VERSION ""

NS_ :

BS_:

BU_:

BO_ 1285 Driver_Controls: 8 Vector__XXX
	SG_ State : 0|16@1+ (1,0) [0|0] "" Vector__XXX

BO_ 1536 BMU_Heatbeat: 0 Vector__XXX
	SG_  : 0|0@1+ (0,0) [0|0] "" Vector__XXX

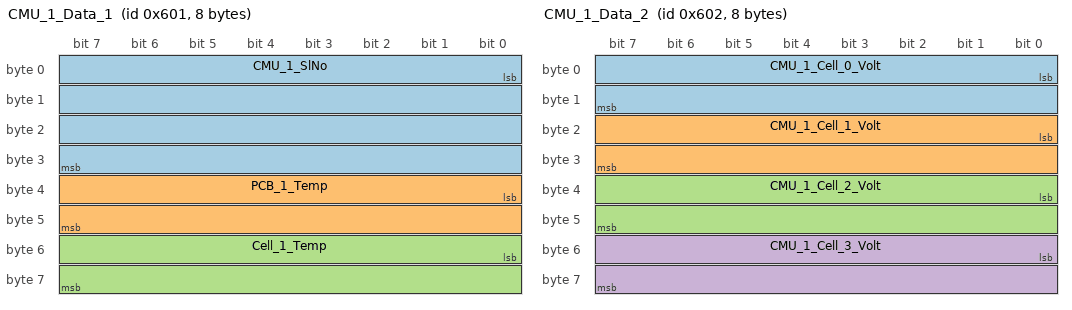
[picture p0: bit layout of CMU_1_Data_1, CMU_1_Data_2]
BO_ 1537 CMU_1_Data_1: 8 Vector__XXX
	SG_ CMU_1_SlNo : 0|32@1+ (1,0) [0|0] "" Vector__XXX
	SG_ PCB_1_Temp : 32|16@1+ (0.1,0) [0|0] "Celcius" Vector__XXX
	SG_ Cell_1_Temp : 48|16@1+ (0.1,0) [0|0] "Celcius" Vector__XXX

BO_ 1538 CMU_1_Data_2: 8 Vector__XXX
	SG_ CMU_1_Cell_0_Volt : 0|16@1+ (1,0) [0|0] "mV" Vector__XXX
	SG_ CMU_1_Cell_1_Volt : 16|16@1+ (1,0) [0|0] "mV" Vector__XXX
	SG_ CMU_1_Cell_2_Volt : 32|16@1+ (1,0) [0|0] "mV" Vector__XXX
	SG_ CMU_1_Cell_3_Volt : 48|16@1+ (1,0) [0|0] "mV" Vector__XXX

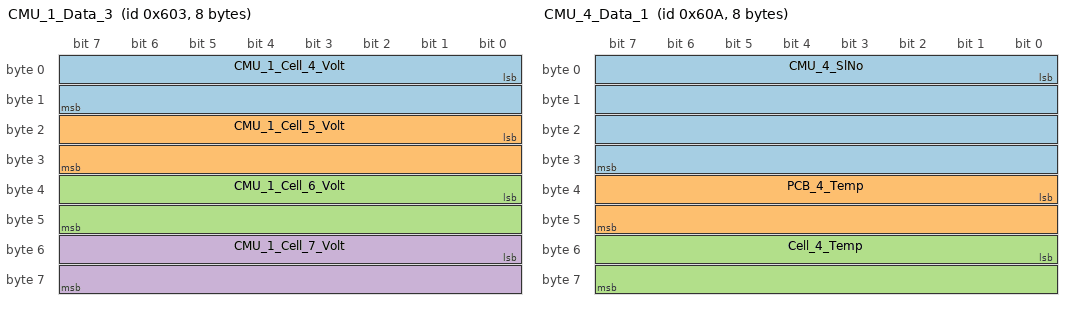
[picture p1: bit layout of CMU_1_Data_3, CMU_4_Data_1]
BO_ 1539 CMU_1_Data_3: 8 Vector__XXX
	SG_ CMU_1_Cell_4_Volt : 0|16@1+ (1,0) [0|0] "mV" Vector__XXX
	SG_ CMU_1_Cell_5_Volt : 16|16@1+ (1,0) [0|0] "mV" Vector__XXX
	SG_ CMU_1_Cell_6_Volt : 32|16@1+ (1,0) [0|0] "mV" Vector__XXX
	SG_ CMU_1_Cell_7_Volt : 48|16@1+ (1,0) [0|0] "mV" Vector__XXX

BO_ 1540 CMU_2_Data_1: 0 Vector__XXX
	SG_ CMU_2_SlNo : 0|32@1+ (1,0) [0|0] "" Vector__XXX
	SG_ PCB_2_Temp : 32|16@1+ (0.1,0) [0|0] "Celcius" Vector__XXX
	SG_ Cell_2_Temp : 48|16@1+ (0.1,0) [0|0] "Celcius" Vector__XXX

BO_ 1541 CMU_2_Data_2: 0 Vector__XXX
	SG_ CMU_2_Cell_0_Volt : 0|16@1+ (1,0) [0|0] "mV" Vector__XXX
	SG_ CMU_2_Cell_1_Volt : 16|16@1+ (1,0) [0|0] "mV" Vector__XXX
	SG_ CMU_2_Cell_2_Volt : 32|16@1+ (1,0) [0|0] "mV" Vector__XXX
	SG_ CMU_2_Cell_3_Volt : 48|16@1+ (1,0) [0|0] "mV" Vector__XXX

BO_ 1542 CMU_2_Data_3: 0 Vector__XXX
	SG_ CMU_2_Cell_4_Volt : 0|16@1+ (1,0) [0|0] "mV" Vector__XXX
	SG_ CMU_2_Cell_5_Volt : 16|16@1+ (1,0) [0|0] "mV" Vector__XXX
	SG_ CMU_2_Cell_6_Volt : 32|16@1+ (1,0) [0|0] "mV" Vector__XXX
	SG_ CMU_2_Cell_7_Volt : 48|16@1+ (1,0) [0|0] "mV" Vector__XXX

BO_ 1543 CMU_3_Data_1: 0 Vector__XXX
	SG_ CMU_3_SlNo : 0|32@1+ (1,0) [0|0] "" Vector__XXX
	SG_ PCB_3_Temp : 32|16@1+ (0.1,0) [0|0] "Celcius" Vector__XXX
	SG_ Cell_3_Temp : 48|16@1+ (0.1,0) [0|0] "Celcius" Vector__XXX

BO_ 1544 CMU_3_Data_2: 0 Vector__XXX
	SG_ CMU_3_Cell_0_Volt : 0|16@1+ (1,0) [0|0] "mV" Vector__XXX
	SG_ CMU_3_Cell_1_Volt : 16|16@1+ (1,0) [0|0] "mV" Vector__XXX
	SG_ CMU_3_Cell_2_Volt : 32|16@1+ (1,0) [0|0] "mV" Vector__XXX
	SG_ CMU_3_Cell_3_Volt : 48|16@1+ (1,0) [0|0] "mV" Vector__XXX

BO_ 1545 CMU_3_Data_3: 0 Vector__XXX
	SG_ CMU_3_Cell_4_Volt : 0|16@1+ (1,0) [0|0] "mV" Vector__XXX
	SG_ CMU_3_Cell_5_Volt : 16|16@1+ (1,0) [0|0] "mV" Vector__XXX
	SG_ CMU_3_Cell_6_Volt : 32|16@1+ (1,0) [0|0] "mV" Vector__XXX
	SG_ CMU_3_Cell_7_Volt : 48|16@1+ (1,0) [0|0] "mV" Vector__XXX

BO_ 1546 CMU_4_Data_1: 8 Vector__XXX
	SG_ CMU_4_SlNo : 0|32@1+ (1,0) [0|0] "" Vector__XXX
	SG_ PCB_4_Temp : 32|16@1+ (0.1,0) [0|0] "Celcius" Vector__XXX
	SG_ Cell_4_Temp : 48|16@1+ (0.1,0) [0|0] "Celcius" Vector__XXX

BO_ 1547 CMU_4_Data_2: 0 Vector__XXX
	SG_ CMU_4_Cell_4_Volt : 0|16@1+ (1,0) [0|0] "mV" Vector__XXX
	SG_ CMU_4_Cell_5_Volt : 16|16@1+ (1,0) [0|0] "mV" Vector__XXX
	SG_ CMU_4_Cell_6_Volt : 32|16@1+ (1,0) [0|0] "mV" Vector__XXX
	SG_ CMU_4_Cell_7_Volt : 48|16@1+ (1,0) [0|0] "mV" Vector__XXX

BO_ 1548 CMU_4_Data_3: 0 Vector__XXX
	SG_ CMU_4_Cell_0_Volt : 0|16@1+ (1,0) [0|0] "mV" Vector__XXX
	SG_ CMU_4_Cell_1_Volt : 16|16@1+ (1,0) [0|0] "mV" Vector__XXX
	SG_ CMU_4_Cell_2_Volt : 32|16@1+ (1,0) [0|0] "mV" Vector__XXX
	SG_ CMU_4_Cell_3_Volt : 48|16@1+ (1,0) [0|0] "mV" Vector__XXX

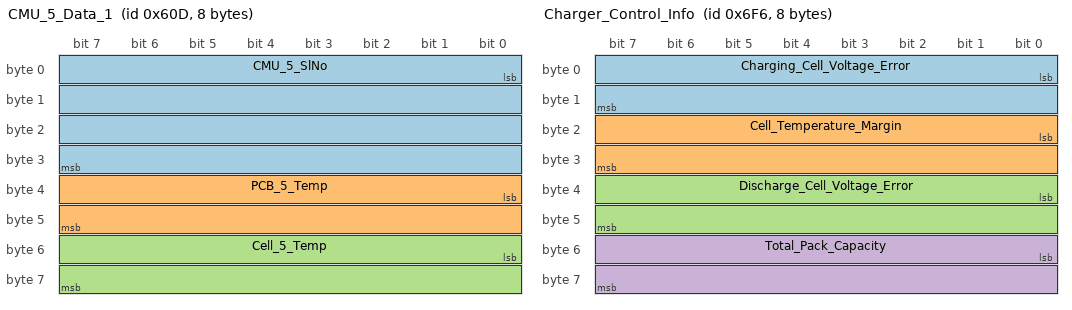
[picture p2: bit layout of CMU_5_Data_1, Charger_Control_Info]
BO_ 1549 CMU_5_Data_1: 8 Vector__XXX
	SG_ CMU_5_SlNo : 0|32@1+ (1,0) [0|0] "" Vector__XXX
	SG_ PCB_5_Temp : 32|16@1+ (0.1,0) [0|0] "Celcius" Vector__XXX
	SG_ Cell_5_Temp : 48|16@1+ (0.1,0) [0|0] "Celcius" Vector__XXX

BO_ 1550 CMU_5_Data_2: 0 Vector__XXX
	SG_ CMU_5_Cell_0_Volt : 0|16@1+ (1,0) [0|0] "mV" Vector__XXX
	SG_ CMU_5_Cell_1_Volt : 16|16@1+ (1,0) [0|0] "mV" Vector__XXX
	SG_ CMU_5_Cell_2_Volt : 32|16@1+ (1,0) [0|0] "mV" Vector__XXX
	SG_ CMU_5_Cell_3_Volt : 48|16@1+ (1,0) [0|0] "mV" Vector__XXX

BO_ 1551 CMU_5_Data_3: 0 Vector__XXX
	SG_ CMU_5_Cell_4_Volt : 0|16@1+ (1,0) [0|0] "mV" Vector__XXX
	SG_ CMU_5_Cell_5_Volt : 16|16@1+ (1,0) [0|0] "mV" Vector__XXX
	SG_ CMU_5_Cell_6_Volt : 32|16@1+ (1,0) [0|0] "mV" Vector__XXX
	SG_ CMU_5_Cell_7_Volt : 48|16@1+ (1,0) [0|0] "mV" Vector__XXX

BO_ 1780 Pack_SOC: 8 Vector__XXX
	SG_ SOC_Ah : 0|32@1+ (1,0) [0|0] "Ah" Vector__XXX
	SG_ SOC_Percent : 32|32@1+ (1,0) [0|0] "Percent" Vector__XXX

BO_ 1781 Balance_SOC: 8 Vector__XXX
	SG_ SOC_Ah : 0|32@1+ (1,0) [0|0] "Ah" Vector__XXX
	SG_ SOC_Percent : 32|32@1+ (1,0) [0|0] "Percent" Vector__XXX

BO_ 1782 Charger_Control_Info: 8 Vector__XXX
	SG_ Charging_Cell_Voltage_Error : 0|16@1+ (1,0) [0|0] "mV" Vector__XXX
	SG_ Cell_Temperature_Margin : 16|16@1+ (0.1,0) [0|0] "Celcius" Vector__XXX
	SG_ Discharge_Cell_Voltage_Error : 32|16@1+ (1,0) [0|0] "mV" Vector__XXX
	SG_ Total_Pack_Capacity : 48|16@1+ (1,0) [0|0] "Ah" Vector__XXX

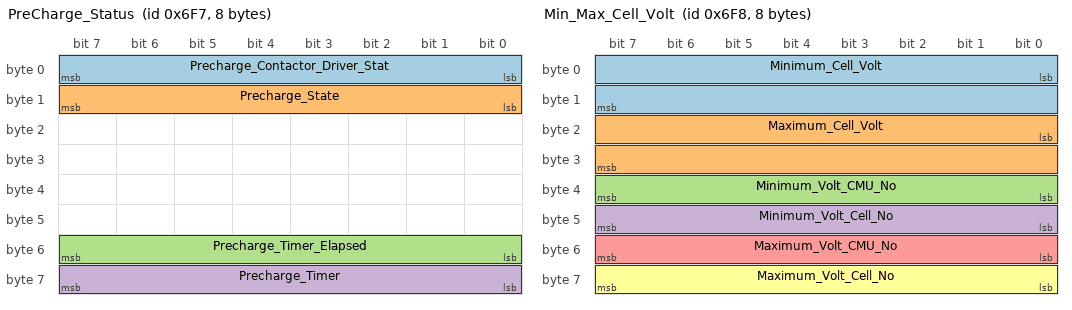
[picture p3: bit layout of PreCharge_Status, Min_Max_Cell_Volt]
BO_ 1783 PreCharge_Status: 8 Vector__XXX
	SG_ Precharge_Contactor_Driver_Stat : 0|8@1+ (1,0) [0|0] "" Vector__XXX
	SG_ Precharge_State : 8|8@1+ (1,0) [0|0] "" Vector__XXX
	SG_ Precharge_Timer_Elapsed : 48|8@1+ (1,0) [0|0] "" Vector__XXX
	SG_ Precharge_Timer : 56|8@1+ (1,10) [0|0] "ms" Vector__XXX

BO_ 1784 Min_Max_Cell_Volt: 8 Vector__XXX
	SG_ Minimum_Cell_Volt : 0|16@1+ (1,0) [0|0] "mV" Vector__XXX
	SG_ Maximum_Cell_Volt : 16|16@1+ (1,0) [0|0] "mV" Vector__XXX
	SG_ Minimum_Volt_CMU_No : 32|8@1+ (1,0) [0|0] "" Vector__XXX
	SG_ Minimum_Volt_Cell_No : 40|8@1+ (1,0) [0|0] "" Vector__XXX
	SG_ Maximum_Volt_CMU_No : 48|8@1+ (1,0) [0|0] "" Vector__XXX
	SG_ Maximum_Volt_Cell_No : 56|8@1+ (1,0) [0|0] "" Vector__XXX

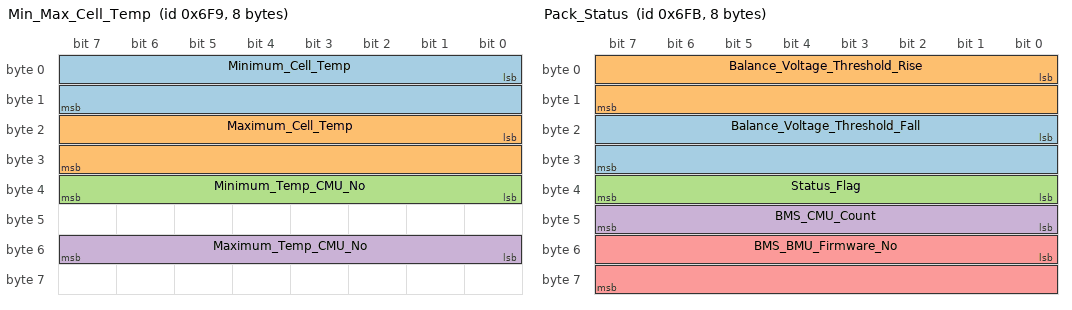
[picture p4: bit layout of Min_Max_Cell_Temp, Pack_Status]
BO_ 1785 Min_Max_Cell_Temp: 8 Vector__XXX
	SG_ Minimum_Cell_Temp : 0|16@1+ (0.1,0) [0|0] "Celcius" Vector__XXX
	SG_ Maximum_Cell_Temp : 16|16@1+ (0.1,0) [0|0] "Celcius" Vector__XXX
	SG_ Minimum_Temp_CMU_No : 32|8@1+ (1,0) [0|0] "" Vector__XXX
	SG_ Maximum_Temp_CMU_No : 48|8@1+ (1,0) [0|0] "" Vector__XXX

BO_ 1786 Battery_Volt_Current: 8 Vector__XXX
	SG_ Battery_Voltage : 0|32@1+ (1,0) [0|0] "mV" Vector__XXX
	SG_ Battery_Current : 32|32@1+ (1,0) [0|0] "mA" Vector__XXX

BO_ 1787 Pack_Status: 8 Vector__XXX
	SG_ Balance_Voltage_Threshold_Fall : 16|16@1+ (1,0) [0|0] "" Vector__XXX
	SG_ Balance_Voltage_Threshold_Rise : 0|16@1+ (1,0) [0|0] "" Vector__XXX
	SG_ Status_Flag : 32|8@1+ (1,0) [0|0] "" Vector__XXX
	SG_ BMS_CMU_Count : 40|8@1+ (1,0) [0|0] "" Vector__XXX
	SG_ BMS_BMU_Firmware_No : 48|16@1+ (1,0) [0|0] "" Vector__XXX

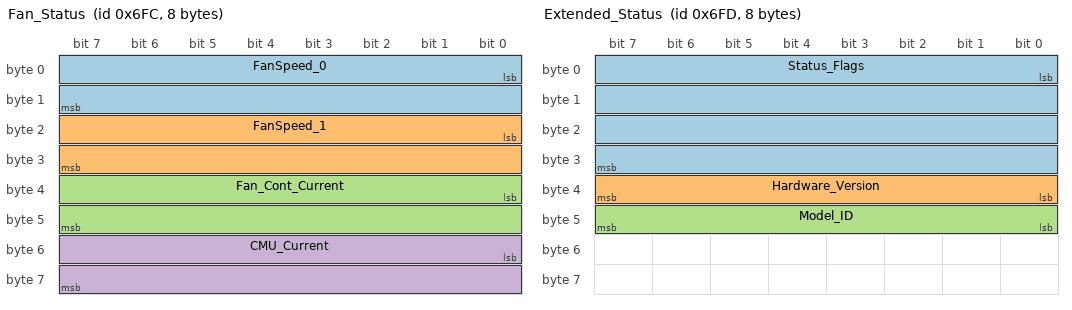
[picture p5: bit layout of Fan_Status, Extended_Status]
BO_ 1788 Fan_Status: 8 Vector__XXX
	SG_ FanSpeed_0 : 0|16@1+ (1,0) [0|0] "rpm" Vector__XXX
	SG_ FanSpeed_1 : 16|16@1+ (1,0) [0|0] "rpm" Vector__XXX
	SG_ Fan_Cont_Current : 32|16@1+ (1,0) [0|0] "mA" Vector__XXX
	SG_ CMU_Current : 48|16@1+ (1,0) [0|0] "mA" Vector__XXX

BO_ 1789 Extended_Status: 8 Vector__XXX
	SG_ Status_Flags : 0|32@1+ (1,0) [0|0] "" Vector__XXX
	SG_ Hardware_Version : 32|8@1+ (1,0) [0|0] "" Vector__XXX
	SG_ Model_ID : 40|8@1+ (1,0) [0|0] "" Vector__XXX

BA_DEF_  "BusType" STRING ;
BA_DEF_DEF_  "BusType" "";
BA_ "BusType" "CAN";

SIG_VALTYPE_ 1780 SOC_Ah : 1;
SIG_VALTYPE_ 1780 SOC_Percent : 1;
SIG_VALTYPE_ 1781 SOC_Ah : 1;
SIG_VALTYPE_ 1781 SOC_Percent : 1;
